# ATtiny25 device description
Architecture: AVR8; Family: tinyAVR
Registers are 8-bit, access not given, no defined reset value unless marked. A register's access mark holds for its fields unless they carry their own. Offsets are from the block's base; [hi:lo] are bit positions.

## EEPROM
Instances: EEPROM 0x00
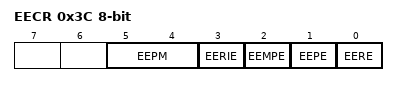
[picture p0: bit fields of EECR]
0x3C EECR — EEPROM Control Register
  [5:4] EEPM — EEPROM Programming Mode Bits
    0=ERASE_AND_WRITE_IN_ONE_OPERATION; 1=ERASE_ONLY; 2=WRITE_ONLY
  [3] EERIE — EEPROM Ready Interrupt Enable
  [2] EEMPE — EEPROM Master Write Enable
  [1] EEPE — EEPROM Write Enable
  [0] EERE — EEPROM Read Enable
0x3D EEDR — EEPROM Data Register
0x3E EEAR 16-bit bits used 8:0 — EEPROM Address Register Bytes

## WDT — Watchdog Timer
Instances: WDT 0x00
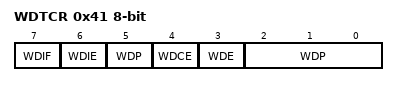
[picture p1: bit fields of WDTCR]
0x41 WDTCR — Watchdog Timer Control Register
  [7] WDIF — Watchdog Timeout Interrupt Flag
  [6] WDIE — Watchdog Timeout Interrupt Enable
  [4] WDCE — Watchdog Change Enable
  [3] WDE — Watch Dog Enable
  [5,2:0] WDP — Watchdog Timer Prescaler Bits
    0=OSCILLATOR_CYCLES_2K; 1=OSCILLATOR_CYCLES_4K; 2=OSCILLATOR_CYCLES_8K; 3=OSCILLATOR_CYCLES_16K; 4=OSCILLATOR_CYCLES_32K; 5=OSCILLATOR_CYCLES_64K; 6=OSCILLATOR_CYCLES_128K; 7=OSCILLATOR_CYCLES_256K; 8=OSCILLATOR_CYCLES_512K; 9=OSCILLATOR_CYCLES_1024K

## TC0 (TC8 module) — Timer/Counter, 8-bit
Instances: TC0 0x00
0x48 OCR0B — Timer/Counter0 Output Compare Register
0x49 OCR0A — Timer/Counter0 Output Compare Register
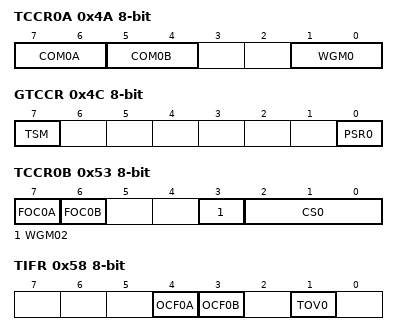
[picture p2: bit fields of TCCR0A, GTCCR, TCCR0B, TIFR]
0x4A TCCR0A — Timer/Counter Control Register A
  [7:6] COM0A — Compare Output Mode, Phase Correct PWM Mode
  [5:4] COM0B — Compare Output Mode, Fast PWm
  [1:0] WGM0 — Waveform Generation Mode
0x4C GTCCR — General Timer/Counter Control Register
  [7] TSM — Timer/Counter Synchronization Mode
  [0] PSR0 — Prescaler Reset Timer/Counter1 and Timer/Counter0
0x52 TCNT0 — Timer/Counter0
0x53 TCCR0B — Timer/Counter Control Register B
  [7] FOC0A — Force Output Compare A
  [6] FOC0B — Force Output Compare B
  [3] WGM02
  [2:0] CS0 — Clock Select
    0=NO_CLOCK_SOURCE_STOPPED; 1=RUNNING_NO_PRESCALING; 2=RUNNING_CLK_8; 3=RUNNING_CLK_64; 4=RUNNING_CLK_256; 5=RUNNING_CLK_1024; 6=RUNNING_EXTCLK_TN_FALLING_EDGE; 7=RUNNING_EXTCLK_TN_RISING_EDGE
0x58 TIFR — Timer/Counter0 Interrupt Flag register
  [4] OCF0A — Timer/Counter0 Output Compare Flag 0A
  [3] OCF0B — Timer/Counter0 Output Compare Flag 0B
  [1] TOV0 — Timer/Counter0 Overflow Flag
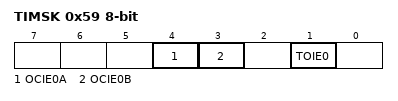
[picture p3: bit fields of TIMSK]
0x59 TIMSK — Timer/Counter Interrupt Mask Register
  [4] OCIE0A — Timer/Counter0 Output Compare Match A Interrupt Enable
  [3] OCIE0B — Timer/Counter0 Output Compare Match B Interrupt Enable
  [1] TOIE0 — Timer/Counter0 Overflow Interrupt Enable

## TC1 (TC8 module) — Timer/Counter, 8-bit
Instances: TC1 0x00
0x43 DTPS — Dead time prescaler register
  [1:0] DTPS
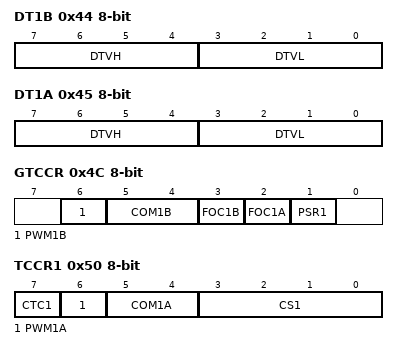
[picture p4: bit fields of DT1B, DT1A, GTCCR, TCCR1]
0x44 DT1B — Dead time value B
  [7:4] DTVH, [3:0] DTVL
0x45 DT1A — Dead time value register
  [7:4] DTVH, [3:0] DTVL
0x4B OCR1B — Output Compare Register
0x4C GTCCR — Timer counter control register
  [6] PWM1B — Pulse Width Modulator B Enable
  [5:4] COM1B — Comparator B Output Mode
  [3] FOC1B — Force Output Compare Match 1B
  [2] FOC1A — Force Output Compare 1A
  [1] PSR1 — Prescaler Reset Timer/Counter1
0x4D OCR1C — Output compare register
0x4E OCR1A — Output Compare Register
0x4F TCNT1 — Timer/Counter Register
0x50 TCCR1 — Timer/Counter Control Register
  [7] CTC1 — Clear Timer/Counter on Compare Match
  [6] PWM1A — Pulse Width Modulator Enable
  [5:4] COM1A — Compare Output Mode, Bits
    0=DISCONNECTED_FROM_OCN_PWMN; 1=TOGGLE_OCN_PWMN_OUTPUT_LINE; 2=CLEAR_OCN_PWMN_OUTPUT_LINE; 3=SET_OCN_PWMN_OUTPUT_LINE
  [3:0] CS1 — Clock Select Bits
    0=NO_CLOCK_SOURCE_STOPPED; 1=RUNNING_NO_PRESCALING; 2=RUNNING_CLK_2; 3=RUNNING_CLK_4; 4=RUNNING_CLK_8; 5=RUNNING_CLK_16; 6=RUNNING_CLK_32; 7=RUNNING_CLK_64; 8=RUNNING_CLK_128; 9=RUNNING_CLK_256; 10=RUNNING_CLK_512; 11=RUNNING_CLK_1024; 12=RUNNING_CLK_2048; 13=RUNNING_CLK_4096; 14=RUNNING_CLK_8192; 15=RUNNING_CLK_16384
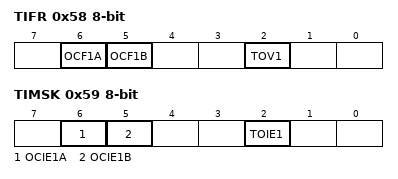
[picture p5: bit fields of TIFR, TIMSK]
0x58 TIFR — Timer/Counter Interrupt Flag Register
  [6] OCF1A — Timer/Counter1 Output Compare Flag 1A
  [5] OCF1B — Timer/Counter1 Output Compare Flag 1B
  [2] TOV1 — Timer/Counter1 Overflow Flag
0x59 TIMSK — Timer/Counter Interrupt Mask Register
  [6] OCIE1A — OCIE1A: Timer/Counter1 Output Compare Interrupt Enable
  [5] OCIE1B — OCIE1A: Timer/Counter1 Output Compare B Interrupt Enable
  [2] TOIE1 — Timer/Counter1 Overflow Interrupt Enable

## BOOT_LOAD — Bootloader
Instances: BOOT_LOAD 0x00
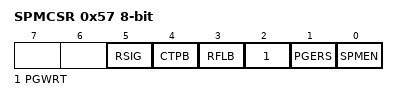
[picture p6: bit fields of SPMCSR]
0x57 SPMCSR — Store Program Memory Control Register
  [5] RSIG — Read Device Signature Imprint Table
  [4] CTPB — Clear temporary page buffer
  [3] RFLB — Read fuse and lock bits
  [2] PGWRT — Page Write
  [1] PGERS — Page Erase
  [0] SPMEN — Store Program Memory Enable

## CPU — CPU Registers
Instances: CPU 0x00
0x31 GPIOR0 — General purpose register 0
0x32 GPIOR1 — General Purpose register 1
0x33 GPIOR2 — General Purpose IO register 2
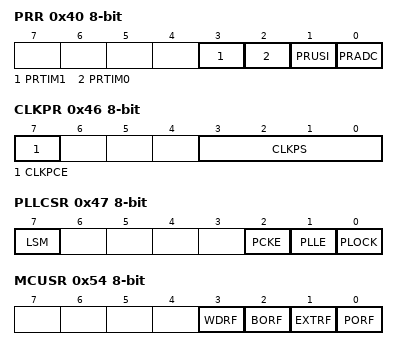
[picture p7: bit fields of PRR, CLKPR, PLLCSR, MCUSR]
0x40 PRR — Power Reduction Register
  [3] PRTIM1 — Power Reduction Timer/Counter1
  [2] PRTIM0 — Power Reduction Timer/Counter0
  [1] PRUSI — Power Reduction USI
  [0] PRADC — Power Reduction ADC
0x42 DWDR — debugWire data register
0x46 CLKPR — Clock Prescale Register
  [7] CLKPCE — Clock Prescaler Change Enable
  [3:0] CLKPS — Clock Prescaler Select Bits
    0=1; 1=2; 2=4; 3=8; 4=16; 5=32; 6=64; 7=128; 8=256
0x47 PLLCSR — PLL Control and status register
  [7] LSM — Low speed mode
  [2] PCKE — PCK Enable
  [1] PLLE — PLL Enable
  [0] PLOCK — PLL Lock detector
0x51 OSCCAL — Oscillator Calibration Register
  [7:0] OSCCAL — Oscillator Calibration
0x54 MCUSR — MCU Status register
  [3] WDRF — Watchdog Reset Flag
  [2] BORF — Brown-out Reset Flag
  [1] EXTRF — External Reset Flag
  [0] PORF — Power-On Reset Flag
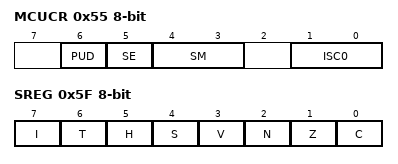
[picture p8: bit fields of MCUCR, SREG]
0x55 MCUCR — MCU Control Register
  [6] PUD — Pull-up Disable
  [5] SE — Sleep Enable
  [4:3] SM — Sleep Mode Select Bits
    0=IDLE; 1=ADC (ADC Noise Reduction (If Available)); 2=PDOWN (Power Down)
  [1:0] ISC0 — Interrupt Sense Control 0 bits
    0=LOW_LEVEL_OF_INTX; 1=ANY_LOGICAL_CHANGE_IN_INTX; 2=FALLING_EDGE_OF_INTX; 3=RISING_EDGE_OF_INTX
0x5D SPL — Stack Pointer Low Byte
0x5F SREG — Status Register
  [7] I — Global Interrupt Enable
  [6] T — Bit Copy Storage
  [5] H — Half Carry Flag
  [4] S — Sign Bit
  [3] V — Two's Complement Overflow Flag
  [2] N — Negative Flag
  [1] Z — Zero Flag
  [0] C — Carry Flag
Value list OSCCAL_VALUE_ADDRESSES: 0=8_0_MHz; 1=6_4_MHz
